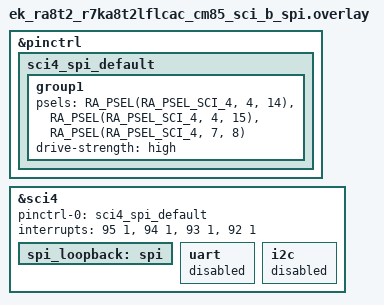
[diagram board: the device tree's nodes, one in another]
/*
 * Copyright (c) 2026 Renesas Electronics Corporation
 * SPDX-License-Identifier: Apache-2.0
 */

#define SPI_LOOPBACK_SLOW_HZ 1000000
#define SPI_LOOPBACK_FAST_HZ 2500000

&pinctrl {
	sci4_spi_default: sci4_spi_default {
		group1 {
			/* MISO4 MOSI4 SCK4 */
			psels = <RA_PSEL(RA_PSEL_SCI_4, 4, 14)>,
				<RA_PSEL(RA_PSEL_SCI_4, 4, 15)>,
				<RA_PSEL(RA_PSEL_SCI_4, 7, 8)>;
			drive-strength = "high";
		};
	};
};

&sci4 {
	pinctrl-0 = <&sci4_spi_default>;
	pinctrl-names = "default";
	interrupts = <95 1>, <94 1>, <93 1>, <92 1>;
	interrupt-names = "rxi", "txi", "tei", "eri";
	status = "okay";

	spi_loopback: spi {
		status = "okay";
	};

	uart {
		status = "disabled";
	};

	i2c {
		status = "disabled";
	};
};

#include "../spi-loopback.dtsi"
